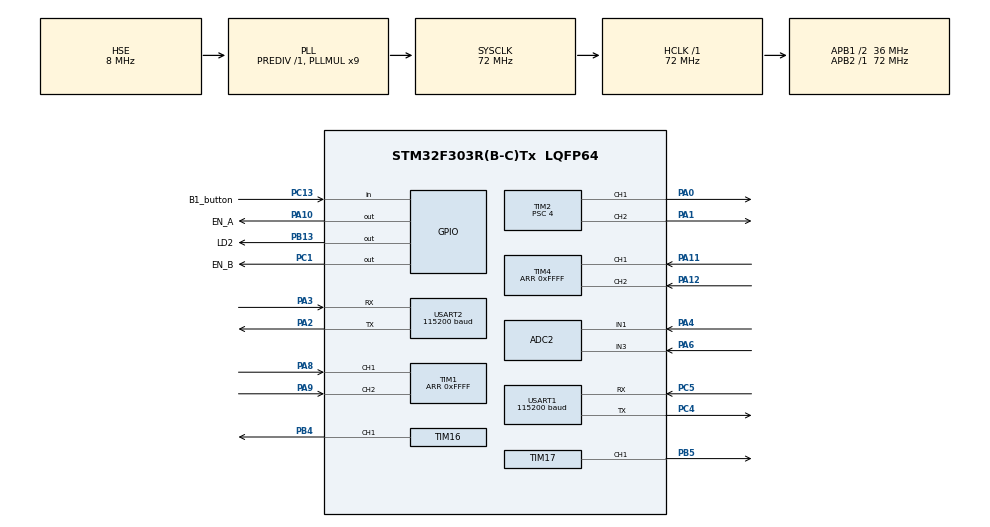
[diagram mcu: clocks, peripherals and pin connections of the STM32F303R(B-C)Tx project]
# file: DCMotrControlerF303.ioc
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ADC2.Channel-0\#ChannelRegularConversion=ADC_CHANNEL_1
ADC2.NbrOfConversionFlag=1
ADC2.Offset-0\#ChannelRegularConversion=0
ADC2.OffsetNumber-0\#ChannelRegularConversion=ADC_OFFSET_NONE
ADC2.Rank-0\#ChannelRegularConversion=1
ADC2.SamplingTime-0\#ChannelRegularConversion=ADC_SAMPLETIME_1CYCLE_5
Dma.ADC2.1.Direction=DMA_PERIPH_TO_MEMORY
Dma.ADC2.1.Instance=DMA2_Channel1
Dma.ADC2.1.MemDataAlignment=DMA_MDATAALIGN_HALFWORD
Dma.ADC2.1.MemInc=DMA_MINC_ENABLE
Dma.ADC2.1.Mode=DMA_CIRCULAR
Dma.ADC2.1.PeriphDataAlignment=DMA_PDATAALIGN_HALFWORD
Dma.ADC2.1.PeriphInc=DMA_PINC_DISABLE
Dma.ADC2.1.Priority=DMA_PRIORITY_LOW
Dma.Request0=USART2_TX
Dma.Request1=ADC2
Dma.USART2_TX.0.Direction=DMA_MEMORY_TO_PERIPH
Dma.USART2_TX.0.Instance=DMA1_Channel7
Dma.USART2_TX.0.MemDataAlignment=DMA_MDATAALIGN_BYTE
Dma.USART2_TX.0.MemInc=DMA_MINC_ENABLE
Dma.USART2_TX.0.Mode=DMA_NORMAL
Dma.USART2_TX.0.PeriphDataAlignment=DMA_PDATAALIGN_BYTE
Dma.USART2_TX.0.PeriphInc=DMA_PINC_DISABLE
Dma.USART2_TX.0.Priority=DMA_PRIORITY_LOW
FREERTOS.HEAP_NUMBER=1
FREERTOS.INCLUDE_vTaskDelayUntil=1
FREERTOS.Tasks01=defaultTask,0,128,StartDefaultTask,Default,NULL,Dynamic,NULL,NULL
FREERTOS.configTOTAL_HEAP_SIZE=16384
FREERTOS.configUSE_MALLOC_FAILED_HOOK=1
FREERTOS.configUSE_TIMERS=1
Mcu.Family=STM32F3
Mcu.Name=STM32F303R(B-C)Tx
Mcu.Package=LQFP64
NVIC.DMA1_Channel7_IRQn=true\:5\:0\:false\:false\:true\:true\:false\:true
NVIC.DMA2_Channel1_IRQn=true\:7\:0\:true\:false\:true\:true\:false\:true
NVIC.PriorityGroup=NVIC_PRIORITYGROUP_4
NVIC.TIM6_DAC_IRQn=true\:0\:0\:false\:false\:true\:false\:false\:true
NVIC.TIM7_IRQn=true\:5\:0\:false\:false\:true\:true\:true\:true
NVIC.TimeBase=TIM6_DAC_IRQn
NVIC.TimeBaseIP=TIM6
NVIC.USART1_IRQn=true\:5\:0\:false\:false\:true\:true\:true\:true
NVIC.USART2_IRQn=true\:9\:0\:true\:false\:true\:true\:true\:true
PA0.Signal=S_TIM2_CH1_ETR
PA1.Signal=S_TIM2_CH2
PA10.GPIO_Label=EN_A
PA10.Signal=GPIO_Output
PA11.Signal=S_TIM4_CH1
PA12.Signal=S_TIM4_CH2
PA13.Mode=Trace_Asynchronous_SW
PA13.Signal=SYS_JTMS-SWDIO
PA14.Mode=Trace_Asynchronous_SW
PA14.Signal=SYS_JTCK-SWCLK
PA2.Mode=Asynchronous
PA2.Signal=USART2_TX
PA3.Mode=Asynchronous
PA3.Signal=USART2_RX
PA4.Mode=IN1-Single-Ended
PA4.Signal=ADC2_IN1
PA6.Mode=IN3-Single-Ended
PA6.Signal=ADC2_IN3
PA8.Signal=S_TIM1_CH1
PA9.Signal=S_TIM1_CH2
PB13.GPIO_Label=LD2
PB13.Signal=GPIO_Output
PB3.Mode=Trace_Asynchronous_SW
PB3.Signal=SYS_JTDO-TRACESWO
PB4.Signal=S_TIM16_CH1
PB5.Signal=S_TIM17_CH1
PC1.GPIO_Label=EN_B
PC1.Signal=GPIO_Output
PC13.GPIO_Label=B1_button
PC13.Signal=GPIO_Input
PC14-OSC32_IN.Mode=LSE-External-Oscillator
PC14-OSC32_IN.Signal=RCC_OSC32_IN
PC15-OSC32_OUT.Mode=LSE-External-Oscillator
PC15-OSC32_OUT.Signal=RCC_OSC32_OUT
PC4.Mode=Asynchronous
PC4.Signal=USART1_TX
PC5.Mode=Asynchronous
PC5.Signal=USART1_RX
PF0-OSC_IN.Mode=HSE-External-Oscillator
PF0-OSC_IN.Signal=RCC_OSC_IN
PF1-OSC_OUT.Mode=HSE-External-Oscillator
PF1-OSC_OUT.Signal=RCC_OSC_OUT
ProjectManager.HeapSize=0x200
ProjectManager.StackSize=0x400
ProjectManager.TargetToolchain=TrueSTUDIO
RCC.AHBFreq_Value=72000000
RCC.APB1CLKDivider=RCC_HCLK_DIV2
RCC.APB1Freq_Value=36000000
RCC.APB1TimFreq_Value=72000000
RCC.APB2Freq_Value=72000000
RCC.APB2TimFreq_Value=72000000
RCC.CortexFreq_Value=72000000
RCC.HCLKFreq_Value=72000000
RCC.HSE_VALUE=8000000
RCC.HSI_VALUE=8000000
RCC.PLLMUL=RCC_PLL_MUL9
RCC.PLLSourceVirtual=RCC_PLLSOURCE_HSE
RCC.SYSCLKFreq_VALUE=72000000
RCC.SYSCLKSourceVirtual=RCC_SYSCLKSOURCE_PLLCLK
RCC.USBFreq_Value=72000000
SH.S_TIM16_CH1.0=TIM16_CH1,PWM Generation1 CH1
SH.S_TIM17_CH1.0=TIM17_CH1,PWM Generation1 CH1
SH.S_TIM1_CH1.0=TIM1_CH1,Encoder_Interface
SH.S_TIM1_CH2.0=TIM1_CH2,Encoder_Interface
SH.S_TIM2_CH1_ETR.0=TIM2_CH1,PWM Generation1 CH1
SH.S_TIM2_CH2.0=TIM2_CH2,PWM Generation2 CH2
SH.S_TIM4_CH1.0=TIM4_CH1,Encoder_Interface
SH.S_TIM4_CH2.0=TIM4_CH2,Encoder_Interface
TIM1.IC1Filter=4
TIM1.IC2Filter=4
TIM1.Period=0xFFFF
TIM16.Channel=TIM_CHANNEL_1
TIM16.Period=1000
TIM16.Prescaler=4
TIM17.Channel=TIM_CHANNEL_1
TIM17.Period=1000
TIM17.Prescaler=4
TIM2.Channel-PWM\ Generation1\ CH1=TIM_CHANNEL_1
TIM2.Channel-PWM\ Generation2\ CH2=TIM_CHANNEL_2
TIM2.Period=1000
TIM2.Prescaler=4
TIM2.TIM_MasterOutputTrigger=TIM_TRGO_OC3REF
TIM4.IC1Filter=4
TIM4.IC2Filter=4
TIM4.Period=0xFFFF
TIM7.Period=9999
TIM7.Prescaler=71
USART1.BaudRate=115200
USART1.VirtualMode-Asynchronous=VM_ASYNC
USART2.BaudRate=115200
USART2.VirtualMode-Asynchronous=VM_ASYNC
VP_FREERTOS_VS_CMSIS_V1.Mode=CMSIS_V1
VP_SYS_VS_tim6.Mode=TIM6
VP_TIM16_VS_ClockSourceINT.Mode=Enable_Timer
VP_TIM17_VS_ClockSourceINT.Mode=Enable_Timer
VP_TIM2_VS_ClockSourceINT.Mode=Internal
VP_TIM7_VS_ClockSourceINT.Mode=Enable_Timer
board=custom

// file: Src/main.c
/* USER CODE BEGIN Header */
/**
  ******************************************************************************
  * @file           : main.c
  * @brief          : Main program body
  ******************************************************************************
  * @attention
  *
  * <h2><center>&copy; Copyright (c) 2020 STMicroelectronics.
  * All rights reserved.</center></h2>
  *
  * This software component is licensed by ST under Ultimate Liberty license
  * SLA0044, the "License"; You may not use this file except in compliance with
  * the License. You may obtain a copy of the License at:
  *                             www.st.com/SLA0044
  *
  ******************************************************************************
  */
/* USER CODE END Header */

#include "main.h"
#include "cmsis_os.h"
#include "adc.h"
#include "dma.h"
#include "tim.h"
#include "usart.h"
#include "gpio.h"

void SystemClock_Config(void);
void MX_FREERTOS_Init(void);

int main(void)
{

  /* MCU Configuration--------------------------------------------------------*/

  /* Reset of all peripherals, Initializes the Flash interface and the Systick. */
  HAL_Init();

  /* Configure the system clock */
  SystemClock_Config();

  /* Initialize all configured peripherals */
  MX_GPIO_Init();
  MX_DMA_Init();
  MX_ADC2_Init();
  MX_TIM1_Init();
  MX_TIM2_Init();
  MX_TIM4_Init();
  MX_TIM16_Init();
  MX_TIM17_Init();
  MX_USART2_UART_Init();
  MX_TIM7_Init();
  MX_USART1_UART_Init();

  /* Call init function for freertos objects (in freertos.c) */
  MX_FREERTOS_Init();

  /* Start scheduler */
  osKernelStart();

  /* We should never get here as control is now taken by the scheduler */

  /* Infinite loop */
  while (1)
  {

  }
}

void SystemClock_Config(void)
{
  RCC_OscInitTypeDef RCC_OscInitStruct = {0};
  RCC_ClkInitTypeDef RCC_ClkInitStruct = {0};
  RCC_PeriphCLKInitTypeDef PeriphClkInit = {0};

  /** Initializes the CPU, AHB and APB busses clocks
  */
  RCC_OscInitStruct.OscillatorType = RCC_OSCILLATORTYPE_HSE;
  RCC_OscInitStruct.HSEState = RCC_HSE_ON;
  RCC_OscInitStruct.HSEPredivValue = RCC_HSE_PREDIV_DIV1;
  RCC_OscInitStruct.HSIState = RCC_HSI_ON;
  RCC_OscInitStruct.PLL.PLLState = RCC_PLL_ON;
  RCC_OscInitStruct.PLL.PLLSource = RCC_PLLSOURCE_HSE;
  RCC_OscInitStruct.PLL.PLLMUL = RCC_PLL_MUL9;
  if (HAL_RCC_OscConfig(&RCC_OscInitStruct) != HAL_OK)
  {
    Error_Handler();
  }
  /** Initializes the CPU, AHB and APB busses clocks
  */
  RCC_ClkInitStruct.ClockType = RCC_CLOCKTYPE_HCLK|RCC_CLOCKTYPE_SYSCLK
                              |RCC_CLOCKTYPE_PCLK1|RCC_CLOCKTYPE_PCLK2;
  RCC_ClkInitStruct.SYSCLKSource = RCC_SYSCLKSOURCE_PLLCLK;
  RCC_ClkInitStruct.AHBCLKDivider = RCC_SYSCLK_DIV1;
  RCC_ClkInitStruct.APB1CLKDivider = RCC_HCLK_DIV2;
  RCC_ClkInitStruct.APB2CLKDivider = RCC_HCLK_DIV1;

  if (HAL_RCC_ClockConfig(&RCC_ClkInitStruct, FLASH_LATENCY_2) != HAL_OK)
  {
    Error_Handler();
  }
  PeriphClkInit.PeriphClockSelection = RCC_PERIPHCLK_USART1|RCC_PERIPHCLK_USART2
                              |RCC_PERIPHCLK_TIM1|RCC_PERIPHCLK_ADC12;
  PeriphClkInit.Usart1ClockSelection = RCC_USART1CLKSOURCE_PCLK2;
  PeriphClkInit.Usart2ClockSelection = RCC_USART2CLKSOURCE_PCLK1;
  PeriphClkInit.Adc12ClockSelection = RCC_ADC12PLLCLK_DIV1;
  PeriphClkInit.Tim1ClockSelection = RCC_TIM1CLK_HCLK;
  if (HAL_RCCEx_PeriphCLKConfig(&PeriphClkInit) != HAL_OK)
  {
    Error_Handler();
  }
}

void HAL_TIM_PeriodElapsedCallback(TIM_HandleTypeDef *htim)
{
  if (htim->Instance == TIM6) {
    HAL_IncTick();
  }
}

void Error_Handler(void)
{
}

/************************ (C) COPYRIGHT STMicroelectronics *****END OF FILE****/

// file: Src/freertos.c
/* USER CODE BEGIN Header */
/**
  ******************************************************************************
  * File Name          : freertos.c
  * Description        : Code for freertos applications
  ******************************************************************************
  * @attention
  *
  * <h2><center>&copy; Copyright (c) 2020 STMicroelectronics.
  * All rights reserved.</center></h2>
  *
  * This software component is licensed by ST under Ultimate Liberty license
  * SLA0044, the "License"; You may not use this file except in compliance with
  * the License. You may obtain a copy of the License at:
  *                             www.st.com/SLA0044
  *
  ******************************************************************************
  */
/* USER CODE END Header */

#include "FreeRTOS.h"
#include "task.h"
#include "main.h"
#include "cmsis_os.h"

/* USER CODE BEGIN Includes */
#include "L6206.h"
#include "tim.h"
#include "stdio.h"
#include "Controler.h"
/* USER CODE END Includes */

osThreadId defaultTaskHandle;

void StartDefaultTask(void const * argument);

void MX_FREERTOS_Init(void); /* (MISRA C 2004 rule 8.1) */

/* GetIdleTaskMemory prototype (linked to static allocation support) */
void vApplicationGetIdleTaskMemory( StaticTask_t **ppxIdleTaskTCBBuffer, StackType_t **ppxIdleTaskStackBuffer, uint32_t *pulIdleTaskStackSize );

/* GetTimerTaskMemory prototype (linked to static allocation support) */
void vApplicationGetTimerTaskMemory( StaticTask_t **ppxTimerTaskTCBBuffer, StackType_t **ppxTimerTaskStackBuffer, uint32_t *pulTimerTaskStackSize );

/* Hook prototypes */
void vApplicationMallocFailedHook(void);

/* USER CODE BEGIN 5 */
__weak void vApplicationMallocFailedHook(void)
{
   /* vApplicationMallocFailedHook() will only be called if
   configUSE_MALLOC_FAILED_HOOK is set to 1 in FreeRTOSConfig.h. It is a hook
   function that will get called if a call to pvPortMalloc() fails.
   pvPortMalloc() is called internally by the kernel whenever a task, queue,
   timer or semaphore is created. It is also called by various parts of the
   demo application. If heap_1.c or heap_2.c are used, then the size of the
   heap available to pvPortMalloc() is defined by configTOTAL_HEAP_SIZE in
   FreeRTOSConfig.h, and the xPortGetFreeHeapSize() API function can be used
   to query the size of free heap space that remains (although it does not
   provide information on how the remaining heap might be fragmented). */
}
/* USER CODE END 5 */

/* USER CODE BEGIN GET_IDLE_TASK_MEMORY */
static StaticTask_t xIdleTaskTCBBuffer;
static StackType_t xIdleStack[configMINIMAL_STACK_SIZE];

void vApplicationGetIdleTaskMemory( StaticTask_t **ppxIdleTaskTCBBuffer, StackType_t **ppxIdleTaskStackBuffer, uint32_t *pulIdleTaskStackSize )
{
  *ppxIdleTaskTCBBuffer = &xIdleTaskTCBBuffer;
  *ppxIdleTaskStackBuffer = &xIdleStack[0];
  *pulIdleTaskStackSize = configMINIMAL_STACK_SIZE;
  /* place for user code */
}
/* USER CODE END GET_IDLE_TASK_MEMORY */

/* USER CODE BEGIN GET_TIMER_TASK_MEMORY */
static StaticTask_t xTimerTaskTCBBuffer;
static StackType_t xTimerStack[configTIMER_TASK_STACK_DEPTH];

void vApplicationGetTimerTaskMemory( StaticTask_t **ppxTimerTaskTCBBuffer, StackType_t **ppxTimerTaskStackBuffer, uint32_t *pulTimerTaskStackSize )
{
  *ppxTimerTaskTCBBuffer = &xTimerTaskTCBBuffer;
  *ppxTimerTaskStackBuffer = &xTimerStack[0];
  *pulTimerTaskStackSize = configTIMER_TASK_STACK_DEPTH;
  /* place for user code */
}
/* USER CODE END GET_TIMER_TASK_MEMORY */

void MX_FREERTOS_Init(void) {

  /* Create the thread(s) */
  /* definition and creation of defaultTask */
  osThreadDef(defaultTask, StartDefaultTask, osPriorityNormal, 0, 128);
  defaultTaskHandle = osThreadCreate(osThread(defaultTask), NULL);

}

void StartDefaultTask(void const * argument)
{
  /* USER CODE BEGIN StartDefaultTask */
	L6206_init();
	L6206_enable(1,1);
	Controler_Init();
  /* Infinite loop */
  for(;;)
  {
	//printf("Encoder CH1:%d CH2:%d \r\n",(int)TIM1->CCR1,(int)TIM1->CCR2);

/*	for(int i=-250;i<250;i+=1){
		osDelay(20);
		L6206_setDuty(i,i);
	}
	for(int i=250;i>-250;i-=1){
		osDelay(20);
		L6206_setDuty(i,i);
	}

	while(1){
		L6206_setDuty(power,power);
		osDelay(200);
	}*/
	osDelay(1000);

  }
  /* USER CODE END StartDefaultTask */
}

/************************ (C) COPYRIGHT STMicroelectronics *****END OF FILE****/
